# ESP32C5_RADIO register map
Vendor: Espressif; Series: ESP32-C5; File version: 0.1
Registers are 32-bit, read-write, no defined reset value unless marked. A register's access mark holds for its fields unless they carry their own. Offsets are from the block's base; [hi:lo] are bit positions.

## PMU_RADIO — ESP32-C5 PMU fields that the PHY drives: the analog I2C power and reset controls of the RF blocks and the immediate BB I2C power tie. Other fields remain absent and are preserved by every field transaction.
Base 0x600B0000
0xCC IMM_HP_CK_POWER reset 0x0 — Immediate HP clock and analog power ties.
  [28] TIE_HIGH_XPD_BB_I2C — Tie the BB analog I2C power high; ESP-IDF declares the field write-trigger.
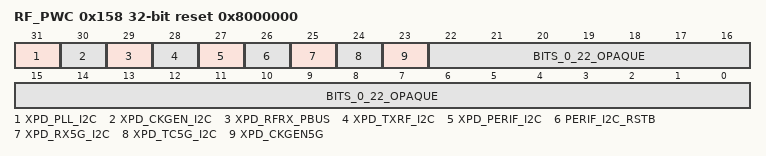
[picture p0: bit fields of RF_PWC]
0x158 RF_PWC reset 0x8000000 — Analog I2C power and reset of the RF blocks.
  [31] XPD_PLL_I2C — Power the analog I2C of the PLL.
  [30] XPD_CKGEN_I2C — Power the analog I2C of the clock generator.
  [29] XPD_RFRX_PBUS — Power the RF receiver PBus.
  [28] XPD_TXRF_I2C — Power the analog I2C of the RF transmitter.
  [27] XPD_PERIF_I2C — Power the peripheral analog I2C.
  [26] PERIF_I2C_RSTB — Release the peripheral analog I2C from reset when set.
  [25] XPD_RX5G_I2C — Power the analog I2C of the 5 GHz receiver.
  [24] XPD_TC5G_I2C — Power the analog I2C of the 5 GHz transceiver.
  [23] XPD_CKGEN5G — Power the 5 GHz clock generator.
  [22:0] BITS_0_22_OPAQUE — Opaque: meaning not established. Observed source use; the individual hardware meaning is unknown.

## LP_AON_RADIO — ESP32-C5 LP_AON field the PHY's power-detector SAR initialization drives. Other fields remain absent and are preserved by every field transaction.
Base 0x600B1000
0x54 SAR_CCT — SAR control word.
  [31:29] SAR2_PWDET_CCT — Three-bit SAR2 power-detector capacitor code.

## APB_SARADC_RADIO — ESP32-C5 APB_SARADC field the PHY's power-detector initialization drives. Other fields remain absent and are preserved by every field transaction.
Base 0x6000E000
0x00 CTRL reset 0x40038240 — SAR ADC control word.
  [29] SARADC2_PWDET_DRV — Drive SAR ADC2 from the power detector.
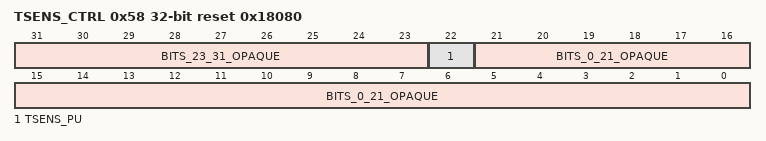
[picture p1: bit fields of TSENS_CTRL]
0x58 TSENS_CTRL reset 0x18080 — Temperature-sensor control.
  [31:23] BITS_23_31_OPAQUE — Opaque: meaning not established. Observed source use; the individual hardware meaning is unknown.
  [22] TSENS_PU — Power up the temperature sensor.
  [21:0] BITS_0_21_OPAQUE — Opaque: meaning not established. Observed source use; the individual hardware meaning is unknown.
0x5C TSENS_CTRL2 reset 0x4002 — Temperature-sensor control 2.
  [15] TSENS_CLK_SEL — Select the temperature-sensor clock.

## PCR_RADIO — ESP32-C5 PCR fields the PHY drives: the SAR ADC and temperature-sensor clocks and one word the public header does not describe. Other fields remain absent and are preserved by every field transaction.
Base 0x60096000
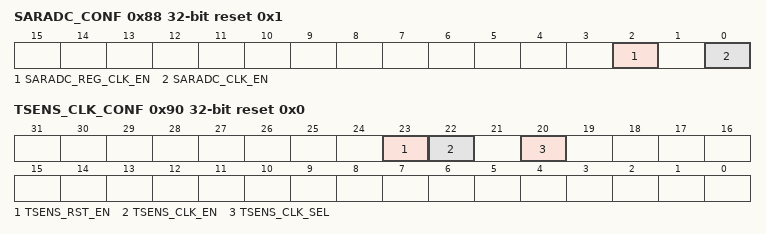
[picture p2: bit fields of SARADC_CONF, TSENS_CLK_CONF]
0x88 SARADC_CONF reset 0x1 — SAR ADC clock and reset.
  [2] SARADC_REG_CLK_EN — Enable the SAR ADC register clock.
  [0] SARADC_CLK_EN — Enable the SAR ADC clock.
0x90 TSENS_CLK_CONF reset 0x0 — Temperature-sensor clock and reset.
  [23] TSENS_RST_EN — Hold the temperature sensor in reset.
  [22] TSENS_CLK_EN — Enable the temperature-sensor clock.
  [20] TSENS_CLK_SEL — Select the temperature-sensor clock source.
0x14C WORD_014C_OPAQUE — Opaque: meaning not established. The public struct reserves the whole word between PCR_SAR_CLK_DIV and PCR_BS_CONF, but pinned phy_rf_init and phy_wakeup_init explicitly replace its low byte with 0x0A; that direct use overrides the reserved claim on low8 only.
  [7:0] BITS_0_7_OPAQUE — Opaque: meaning not established. Low byte; meaning unknown.

## LPPERI_RNG — Low-power peripheral registers: the random number generator's clock gate, its sampling and timer configuration and its synchronized output.
Base 0x600B2800
0x00 CLK_EN reset 0x7F000000 — Clock gates of the low-power peripherals. The word is shared with the LP UART, LP IO, LP I2C, eFuse and LP CPU gates; only the generator's gate is described, and every change keeps the other bits.
  [24] RNG_CK_EN — Random number generator clock enable; set after reset.
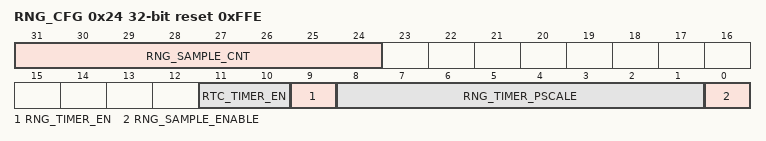
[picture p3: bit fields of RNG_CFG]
0x24 RNG_CFG reset 0xFFE — Random number generator sampling and timer configuration.
  [31:24] RNG_SAMPLE_CNT ro — Count of ring-oscillator samples.
  [11:10] RTC_TIMER_EN — XORs the RTC timer into the output: bit 0 before the CRC, bit 1 after it.
  [9] RNG_TIMER_EN — XORs the asynchronous generator timer into the output.
  [8:1] RNG_TIMER_PSCALE — Clock divider of the generator's timer.
  [0] RNG_SAMPLE_ENABLE — Enables sampling of the ring oscillator; clear after reset.
0x28 RNG_DATA_SYNC ro reset 0x0 — The generator's output, synchronized to the bus clock.
  [31:0] RND_SYNC_DATA — One 32-bit word of random data.
